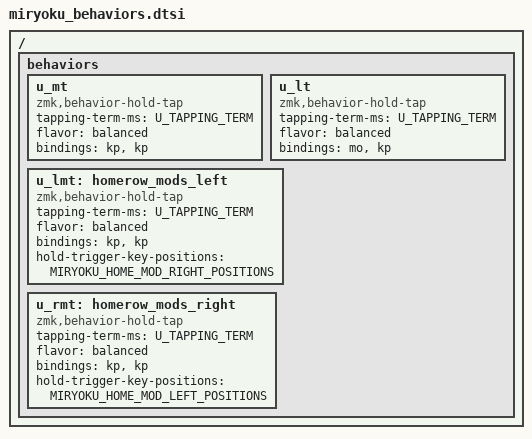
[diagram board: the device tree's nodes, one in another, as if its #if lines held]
// Copyright 2022 Manna Harbour
// https://github.com/manna-harbour/miryoku

/ {
  behaviors {
    u_mt: u_mt {
      compatible = "zmk,behavior-hold-tap";
      #binding-cells = <2>;
      tapping-term-ms = <U_TAPPING_TERM>;
      flavor = "balanced";
      bindings = <&kp>, <&kp>;
    };
    u_lt: u_lt {
      compatible = "zmk,behavior-hold-tap";
      #binding-cells = <2>;
      tapping-term-ms = <U_TAPPING_TERM>;
      flavor = "balanced";
      bindings = <&mo>, <&kp>;
    };
    u_lmt: homerow_mods_left {
      compatible = "zmk,behavior-hold-tap";
      #binding-cells = <2>;
      tapping-term-ms = <U_TAPPING_TERM>;
      flavor = "balanced";
      bindings = <&kp>, <&kp>;
      #if defined (MIRYOKU_HOME_MOD_RIGHT_POSITIONS)
        hold-trigger-key-positions = MIRYOKU_HOME_MOD_RIGHT_POSITIONS ;
      #endif
    };
    u_rmt: homerow_mods_right {
      compatible = "zmk,behavior-hold-tap";
      #binding-cells = <2>;
      tapping-term-ms = <U_TAPPING_TERM>;
      flavor = "balanced";
      bindings = <&kp>, <&kp>;
      #if defined (MIRYOKU_HOME_MOD_LEFT_POSITIONS)
        hold-trigger-key-positions = MIRYOKU_HOME_MOD_LEFT_POSITIONS ;
      #endif
    };
  };
};
